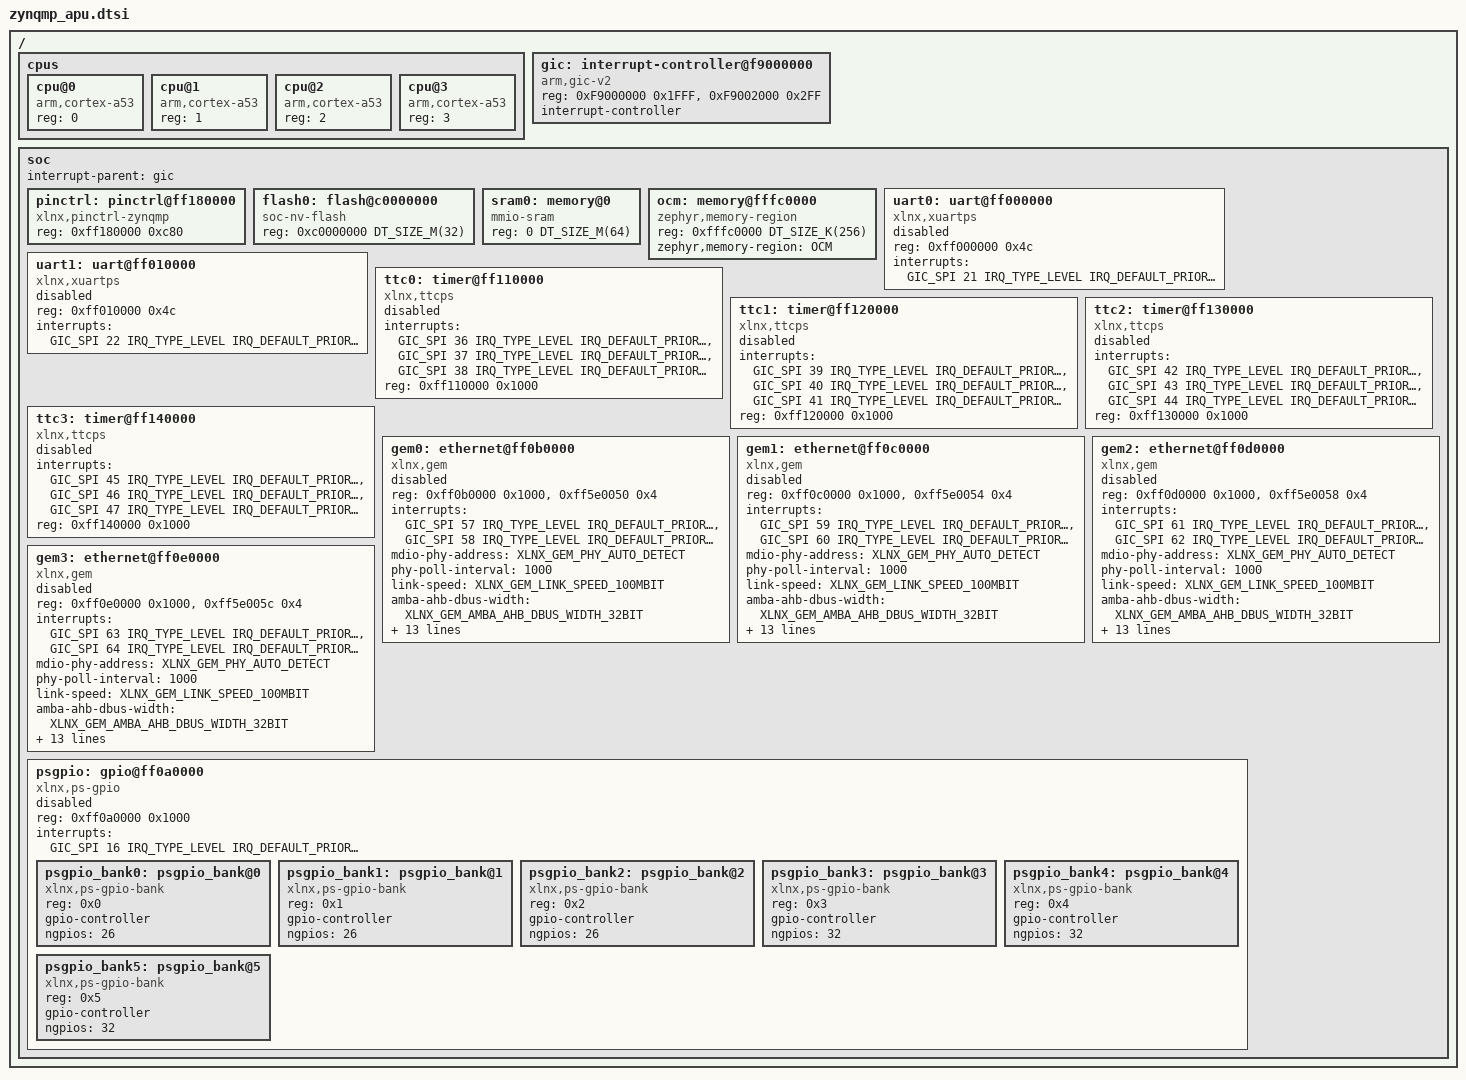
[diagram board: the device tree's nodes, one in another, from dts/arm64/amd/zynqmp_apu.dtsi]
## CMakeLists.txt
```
cmake_minimum_required(VERSION 3.13.2)

set(BOARD_FLASH_RUNNER "openocd")

set(BOARD "mercury_xu_apu")
set(BOARD_ROOT "${CMAKE_SOURCE_DIR}")
set(SOC_ROOT "${CMAKE_SOURCE_DIR}")

# set(SHIELD "gorilla_empty")

add_compile_definitions(FW_DBG_LVL=4)

# set(CMAKE_EXPORT_COMPILE_COMMANDS Y)

find_package(Zephyr REQUIRED HINTS $ENV{ZEPHYR_BASE})

project(app)

set(srcDir "src")
set (gDir ${CMAKE_SOURCE_DIR}/gen)
set (sDir ${CMAKE_SOURCE_DIR}/src)

include("${CMAKE_SOURCE_DIR}/src/demo.cmake")
```

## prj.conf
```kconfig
# no boot banner please
CONFIG_BOOT_BANNER=n

# enable system reboot functions
CONFIG_REBOOT=y

# debug options
CONFIG_DEBUG=y
CONFIG_DEBUG_OPTIMIZATIONS=y
CONFIG_MISRA_SANE=y
```

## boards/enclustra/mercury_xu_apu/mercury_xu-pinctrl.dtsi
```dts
/*
 * Copyright (c) 2025, Stefan Jaritz
 *
 * SPDX-License-Identifier: Apache-2.0
 */

#include <dt-bindings/pinctrl/pinctrl-zynqmp.h>

&pinctrl {
	uart0_default: uart0_default {
		group1 {
			pinmux = <UART0_RX_38>;
		};
		group2 {
			pinmux = <UART0_TX_39>;
		};
	};
	uart1_default: uart1_default {
		group1 {
			pinmux = <UART1_RX_21>;
		};
		group2 {
			pinmux = <UART1_TX_20>;
		};
	};

};
```

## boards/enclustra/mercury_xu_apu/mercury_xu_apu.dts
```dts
/*
 * Copyright (c) 2025, Stefan Jaritz
 *
 * SPDX-License-Identifier: Apache-2.0
 */

/dts-v1/;
#include <arm64/amd/zynqmp_apu.dtsi>
#include "mercury_xu-pinctrl.dtsi"

/ {
	model = "Mercury XU APU";
	compatible = "amd,zynqmp_apu";

	chosen {
		zephyr,console = &uart0;
		zephyr,shell-uart = &uart0;
		zephyr,sram = &sram0;
		zephyr,flash = &flash0;
	};

	fpga0: fpga {
		status = "okay";
		compatible = "xlnx,fpga";
	};
};

&uart0 {
	status = "okay";
	current-speed = <115200>;
	clock-frequency = <99999901>;
	pinctrl-0 = <&uart0_default>;
	pinctrl-names = "default";
};

&uart1 {
	pinctrl-0 = <&uart1_default>;
	pinctrl-names = "default";
};

&ttc0 {
	status = "okay";
	clock-frequency = <5000000>;
};

&psgpio {
	status = "okay";
};
```

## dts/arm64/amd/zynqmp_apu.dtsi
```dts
/*
 * Copyright (c) 2025, Stefan Jaritz
 *
 * SPDX-License-Identifier: Apache-2.0
 */

#include <mem.h>
#include <arm64/armv8-a.dtsi>
#include <zephyr/dt-bindings/interrupt-controller/arm-gic.h>
#include <zephyr/dt-bindings/ethernet/xlnx_gem.h>

/ {
	cpus {
		#address-cells = <1>;
		#size-cells = <0>;

		cpu@0 {
			device_type = "cpu";
			compatible = "arm,cortex-a53";
			reg = <0>;
		};

		cpu@1 {
			device_type = "cpu";
			compatible = "arm,cortex-a53";
			reg = <1>;
		};

		cpu@2 {
			device_type = "cpu";
			compatible = "arm,cortex-a53";
			reg = <2>;
		};

		cpu@3 {
			device_type = "cpu";
			compatible = "arm,cortex-a53";
			reg = <3>;
		};

	};
/*
	timer {
		compatible = "arm,armv8-timer";
		interrupt-parent = <&gic>;
		interrupts = <GIC_PPI 13 IRQ_TYPE_LEVEL
			      IRQ_DEFAULT_PRIORITY>,
			     <GIC_PPI 14 IRQ_TYPE_LEVEL
			      IRQ_DEFAULT_PRIORITY>,
			     <GIC_PPI 11 IRQ_TYPE_LEVEL
			      IRQ_DEFAULT_PRIORITY>,
			     <GIC_PPI 10 IRQ_TYPE_LEVEL
			      IRQ_DEFAULT_PRIORITY>;
	};
*/	
	gic: interrupt-controller@f9000000 {
		compatible = "arm,gic-v2", "arm,gic";
		// reg = <0x38800000 0x10000>, /* GIC Dist */
		//      <0x38880000 0xc0000>; /* GICR (RD_base + SGI_base) */

		// 0xF900_0000 to 0xF900_1FFF GIC distributor.
		// 0xF900_2000 to 0xF900_2FFF GICC interface.
		reg = <0xF9000000 0x1FFF>, /* GIC Dist */
		      <0xF9002000 0x2FF>; /* GICC interface */

		interrupt-controller;
		#interrupt-cells = <4>;
		status = "okay";
	};

	soc {
		interrupt-parent = <&gic>;
		
		pinctrl: pinctrl@ff180000 {
			reg = <0xff180000 0xc80>;
			compatible = "xlnx,pinctrl-zynqmp";
		};
		flash0: flash@c0000000 {
			compatible = "soc-nv-flash";
			reg = <0xc0000000 DT_SIZE_M(32)>;
		};

		sram0: memory@0 {
			compatible = "mmio-sram";
			reg = <0 DT_SIZE_M(64)>;
		};

		ocm: memory@fffc0000 {
			compatible = "zephyr,memory-region", "xlnx,zynq-ocm";
			reg = <0xfffc0000 DT_SIZE_K(256)>;
			zephyr,memory-region = "OCM";
		};

		uart0: uart@ff000000 {
			compatible = "xlnx,xuartps";
			reg = <0xff000000 0x4c>;
			status = "disabled";
			interrupts = <GIC_SPI 21 IRQ_TYPE_LEVEL
					IRQ_DEFAULT_PRIORITY>;
			interrupt-names = "irq_0";
		};

		uart1: uart@ff010000 {
			compatible = "xlnx,xuartps";
			reg = <0xff010000 0x4c>;
			status = "disabled";
			interrupts = <GIC_SPI 22 IRQ_TYPE_LEVEL
					IRQ_DEFAULT_PRIORITY>;
			interrupt-names = "irq_0";
		};

		ttc0: timer@ff110000 {
			compatible = "xlnx,ttcps";
			status = "disabled";
			interrupts = <GIC_SPI 36 IRQ_TYPE_LEVEL
					IRQ_DEFAULT_PRIORITY>,
				     <GIC_SPI 37 IRQ_TYPE_LEVEL
					IRQ_DEFAULT_PRIORITY>,
				     <GIC_SPI 38 IRQ_TYPE_LEVEL
					IRQ_DEFAULT_PRIORITY>;
			interrupt-names = "irq_0", "irq_1", "irq_2";
			reg = <0xff110000 0x1000>;
		};

		ttc1: timer@ff120000 {
			compatible = "xlnx,ttcps";
			status = "disabled";
			interrupts = <GIC_SPI 39 IRQ_TYPE_LEVEL
					IRQ_DEFAULT_PRIORITY>,
				     <GIC_SPI 40 IRQ_TYPE_LEVEL
					IRQ_DEFAULT_PRIORITY>,
				     <GIC_SPI 41 IRQ_TYPE_LEVEL
					IRQ_DEFAULT_PRIORITY>;
			interrupt-names = "irq_0", "irq_1", "irq_2";
			reg = <0xff120000 0x1000>;
		};

		ttc2: timer@ff130000 {
			compatible = "xlnx,ttcps";
			status = "disabled";
			interrupts = <GIC_SPI 42 IRQ_TYPE_LEVEL
					IRQ_DEFAULT_PRIORITY>,
				     <GIC_SPI 43 IRQ_TYPE_LEVEL
					IRQ_DEFAULT_PRIORITY>,
				     <GIC_SPI 44 IRQ_TYPE_LEVEL
					IRQ_DEFAULT_PRIORITY>;
			interrupt-names = "irq_0", "irq_1", "irq_2";
			reg = <0xff130000 0x1000>;
		};

		ttc3: timer@ff140000 {
			compatible = "xlnx,ttcps";
			status = "disabled";
			interrupts = <GIC_SPI 45 IRQ_TYPE_LEVEL
					IRQ_DEFAULT_PRIORITY>,
				     <GIC_SPI 46 IRQ_TYPE_LEVEL
					IRQ_DEFAULT_PRIORITY>,
				     <GIC_SPI 47 IRQ_TYPE_LEVEL
					IRQ_DEFAULT_PRIORITY>;
			interrupt-names = "irq_0", "irq_1", "irq_2";
			reg = <0xff140000 0x1000>;
		};

		gem0: ethernet@ff0b0000 {
			compatible = "xlnx,gem";
			reg = <0xff0b0000 0x1000>,
				<0xff5e0050 0x4>;
			status = "disabled";
			interrupts = <GIC_SPI 57 IRQ_TYPE_LEVEL
					IRQ_DEFAULT_PRIORITY>,
				     <GIC_SPI 58 IRQ_TYPE_LEVEL
					IRQ_DEFAULT_PRIORITY>;
			interrupt-names = "irq_0", "irq_1";
			mdio-phy-address = <XLNX_GEM_PHY_AUTO_DETECT>;
			phy-poll-interval = <1000>;
			link-speed = <XLNX_GEM_LINK_SPEED_100MBIT>;
			amba-ahb-dbus-width = <XLNX_GEM_AMBA_AHB_DBUS_WIDTH_32BIT>;
			amba-ahb-burst-length = <XLNX_GEM_AMBA_AHB_BURST_SINGLE>;
			hw-rx-buffer-size = <XLNX_GEM_HW_RX_BUFFER_SIZE_8KB>;
			hw-rx-buffer-offset = <0>;
			hw-tx-buffer-size-full;
			rx-buffer-descriptors = <32>;
			tx-buffer-descriptors = <32>;
			rx-buffer-size = <512>;
			tx-buffer-size = <512>;
			discard-rx-fcs;
			unicast-hash;
			full-duplex;
		};

		gem1: ethernet@ff0c0000 {
			compatible = "xlnx,gem";
			reg = <0xff0c0000 0x1000>,
				<0xff5e0054 0x4>;
			status = "disabled";
			interrupts = <GIC_SPI 59 IRQ_TYPE_LEVEL
					IRQ_DEFAULT_PRIORITY>,
				     <GIC_SPI 60 IRQ_TYPE_LEVEL
					IRQ_DEFAULT_PRIORITY>;
			interrupt-names = "irq_0", "irq_1";
			mdio-phy-address = <XLNX_GEM_PHY_AUTO_DETECT>;
			phy-poll-interval = <1000>;
			link-speed = <XLNX_GEM_LINK_SPEED_100MBIT>;
			amba-ahb-dbus-width = <XLNX_GEM_AMBA_AHB_DBUS_WIDTH_32BIT>;
			amba-ahb-burst-length = <XLNX_GEM_AMBA_AHB_BURST_SINGLE>;
			hw-rx-buffer-size = <XLNX_GEM_HW_RX_BUFFER_SIZE_8KB>;
			hw-rx-buffer-offset = <0>;
			hw-tx-buffer-size-full;
			rx-buffer-descriptors = <32>;
			tx-buffer-descriptors = <32>;
			rx-buffer-size = <512>;
			tx-buffer-size = <512>;
			discard-rx-fcs;
			unicast-hash;
			full-duplex;
		};

		gem2: ethernet@ff0d0000 {
			compatible = "xlnx,gem";
			reg = <0xff0d0000 0x1000>,
				<0xff5e0058 0x4>;
			status = "disabled";
			interrupts = <GIC_SPI 61 IRQ_TYPE_LEVEL
					IRQ_DEFAULT_PRIORITY>,
				     <GIC_SPI 62 IRQ_TYPE_LEVEL
					IRQ_DEFAULT_PRIORITY>;
			interrupt-names = "irq_0", "irq_1";
			mdio-phy-address = <XLNX_GEM_PHY_AUTO_DETECT>;
			phy-poll-interval = <1000>;
			link-speed = <XLNX_GEM_LINK_SPEED_100MBIT>;
			amba-ahb-dbus-width = <XLNX_GEM_AMBA_AHB_DBUS_WIDTH_32BIT>;
			amba-ahb-burst-length = <XLNX_GEM_AMBA_AHB_BURST_SINGLE>;
			hw-rx-buffer-size = <XLNX_GEM_HW_RX_BUFFER_SIZE_8KB>;
			hw-rx-buffer-offset = <0>;
			hw-tx-buffer-size-full;
			rx-buffer-descriptors = <32>;
			tx-buffer-descriptors = <32>;
			rx-buffer-size = <512>;
			tx-buffer-size = <512>;
			discard-rx-fcs;
			unicast-hash;
			full-duplex;
		};

		gem3: ethernet@ff0e0000 {
			compatible = "xlnx,gem";
			reg = <0xff0e0000 0x1000>,
				<0xff5e005c 0x4>;
			status = "disabled";
			interrupts = <GIC_SPI 63 IRQ_TYPE_LEVEL
					IRQ_DEFAULT_PRIORITY>,
				     <GIC_SPI 64 IRQ_TYPE_LEVEL
					IRQ_DEFAULT_PRIORITY>;
			interrupt-names = "irq_0", "irq_1";
			mdio-phy-address = <XLNX_GEM_PHY_AUTO_DETECT>;
			phy-poll-interval = <1000>;
			link-speed = <XLNX_GEM_LINK_SPEED_100MBIT>;
			amba-ahb-dbus-width = <XLNX_GEM_AMBA_AHB_DBUS_WIDTH_32BIT>;
			amba-ahb-burst-length = <XLNX_GEM_AMBA_AHB_BURST_SINGLE>;
			hw-rx-buffer-size = <XLNX_GEM_HW_RX_BUFFER_SIZE_8KB>;
			hw-rx-buffer-offset = <0>;
			hw-tx-buffer-size-full;
			rx-buffer-descriptors = <32>;
			tx-buffer-descriptors = <32>;
			rx-buffer-size = <512>;
			tx-buffer-size = <512>;
			discard-rx-fcs;
			unicast-hash;
			full-duplex;
		};

		psgpio: gpio@ff0a0000 {
			compatible = "xlnx,ps-gpio";
			status = "disabled";
			reg = <0xff0a0000 0x1000>;
			interrupts = <GIC_SPI 16 IRQ_TYPE_LEVEL
					IRQ_DEFAULT_PRIORITY>;
			interrupt-names = "irq_0";

			#address-cells = <1>;
			#size-cells = <0>;

			psgpio_bank0: psgpio_bank@0 {
				compatible = "xlnx,ps-gpio-bank";
				reg = <0x0>;
				gpio-controller;
				#gpio-cells = <2>;
				ngpios = <26>;
				status = "okay";
			};

			psgpio_bank1: psgpio_bank@1 {
				compatible = "xlnx,ps-gpio-bank";
				reg = <0x1>;
				gpio-controller;
				#gpio-cells = <2>;
				ngpios = <26>;
				status = "okay";
			};

			psgpio_bank2: psgpio_bank@2 {
				compatible = "xlnx,ps-gpio-bank";
				reg = <0x2>;
				gpio-controller;
				#gpio-cells = <2>;
				ngpios = <26>;
				status = "okay";
			};

			psgpio_bank3: psgpio_bank@3 {
				compatible = "xlnx,ps-gpio-bank";
				reg = <0x3>;
				gpio-controller;
				#gpio-cells = <2>;
				ngpios = <32>;
				status = "okay";
			};

			psgpio_bank4: psgpio_bank@4 {
				compatible = "xlnx,ps-gpio-bank";
				reg = <0x4>;
				gpio-controller;
				#gpio-cells = <2>;
				ngpios = <32>;
				status = "okay";
			};

			psgpio_bank5: psgpio_bank@5 {
				compatible = "xlnx,ps-gpio-bank";
				reg = <0x5>;
				gpio-controller;
				#gpio-cells = <2>;
				ngpios = <32>;
				status = "okay";
			};
		};
	};

};
```

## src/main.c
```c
/*
 * Copyright (c) 2025, Stefan Jaritz
 *
 */

#include <stddef.h>
#include <string.h>
#include <errno.h>

#include <stdio.h>
#include <zephyr/kernel.h>
#include <zephyr/drivers/gpio.h>

#include <zephyr/logging/log.h>
#include <zephyr/logging/log_ctrl.h>
#include <zephyr/sys/reboot.h>

#include "_gen_buildNumber.h"
#include "dbglog.h"
#include "threadCfg.h"
#include "version.h"

LOG_MODULE_REGISTER(main, LOG_LEVEL_APP_MAIN);

typedef struct main_s {
	struct k_sem exitSem;
	bool rebootFlag;
} main_t;


main_t mainVar;

void main_gotoStandby(void) {
	LOG_DBG("activate standby");
	mainVar.rebootFlag = false;
	k_sem_give(&mainVar.exitSem);
}

void main_reboot(void) {
	LOG_DBG("trigger reboot");
	mainVar.rebootFlag = true;
	k_sem_give(&mainVar.exitSem);
}

int main(void) {
	k_sem_init(&mainVar.exitSem, 0, 0xFF);
	mainVar.rebootFlag = true;

	LOG_INF("starting %s on Zephyr v%u.%u.%u",
		//log_strdup(FW_VERSION),
		FW_VERSION,
		(unsigned int)SYS_KERNEL_VER_MAJOR(sys_kernel_version_get()),
		(unsigned int)SYS_KERNEL_VER_MINOR(sys_kernel_version_get()),
		(unsigned int)SYS_KERNEL_VER_PATCHLEVEL(sys_kernel_version_get())
	);

standby:
	k_thread_priority_set(k_current_get(), THREAD_PRIO_IDLE);
	LOG_DBG("startup done");
	k_sem_take(&mainVar.exitSem, K_FOREVER);

	if (false == mainVar.rebootFlag) {
		// enter standby
	} else {
		sys_reboot(SYS_REBOOT_COLD);
		sys_reboot(SYS_REBOOT_WARM);
	}
	return 0;
}

void k_sys_fatal_error_handler(unsigned int reason, const struct arch_esf * esf) {
	LOG_PANIC();
/*	for (;;) {

	}
*/
	sys_reboot(SYS_REBOOT_COLD);
	sys_reboot(SYS_REBOOT_WARM);
}
```

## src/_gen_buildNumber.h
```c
/*
 * _gen_buildNumber.h
 *
 *  generated 2025-01-18 21:38:34.462481
 * 
 */

#ifndef BUILD_NUMBER_H_
#define BUILD_NUMBER_H_

// firmware version
#define FW_BUILD_NUMBER 49

#endif /* BUILD_NUMBER_H_ */
```

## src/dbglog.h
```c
/*
 * debugLog.h
 *
* Copyright (c) 2025, Stefan Jaritz
*/

#ifndef DBGLOG_H_
#define DBGLOG_H_

// set the debug level if it is not set before
#ifndef FW_DBG_LVL
	#define FW_DBG_LVL 4
#endif

// main
#define LOG_LEVEL_APP_MAIN FW_DBG_LVL

#endif /* DBGLOG_H_ */
```

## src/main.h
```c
/*
 * Copyright (c) 2025, Stefan Jaritz
 */

#ifndef MAIN_H_
#define MAIN_H_

void main_gotoStandby(void);
void main_reboot(void);

#endif /* MAIN_H_ */
```

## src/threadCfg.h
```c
/*
 * Copyright (c) 2025, Stefan Jaritz
 */

#ifndef THREADCFG_H_
#define THREADCFG_H_

#define THREAD_STACK_SIZE 3072
#define THREAD_BIG_STACK_SIZE 4096
/* scheduling priority used by each thread */
// prios (lower number gets prio over higher number)

#define THREAD_PRIO_IDLE 13

#endif /* THREADCFG_H_ */
```

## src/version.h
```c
/*
 * Copyright (c) 2025, Stefan Jaritz
 */

#ifndef VERSION_H_
#define VERSION_H_

#include "_gen_buildNumber.h"

#define STR_HELPER(x) #x
#define STR(x) STR_HELPER(x)

// firmware version
#define FW_VERSION "v0.1.0(b" STR(FW_BUILD_NUMBER) ")"

#endif /* VERSION_H_ */
```
